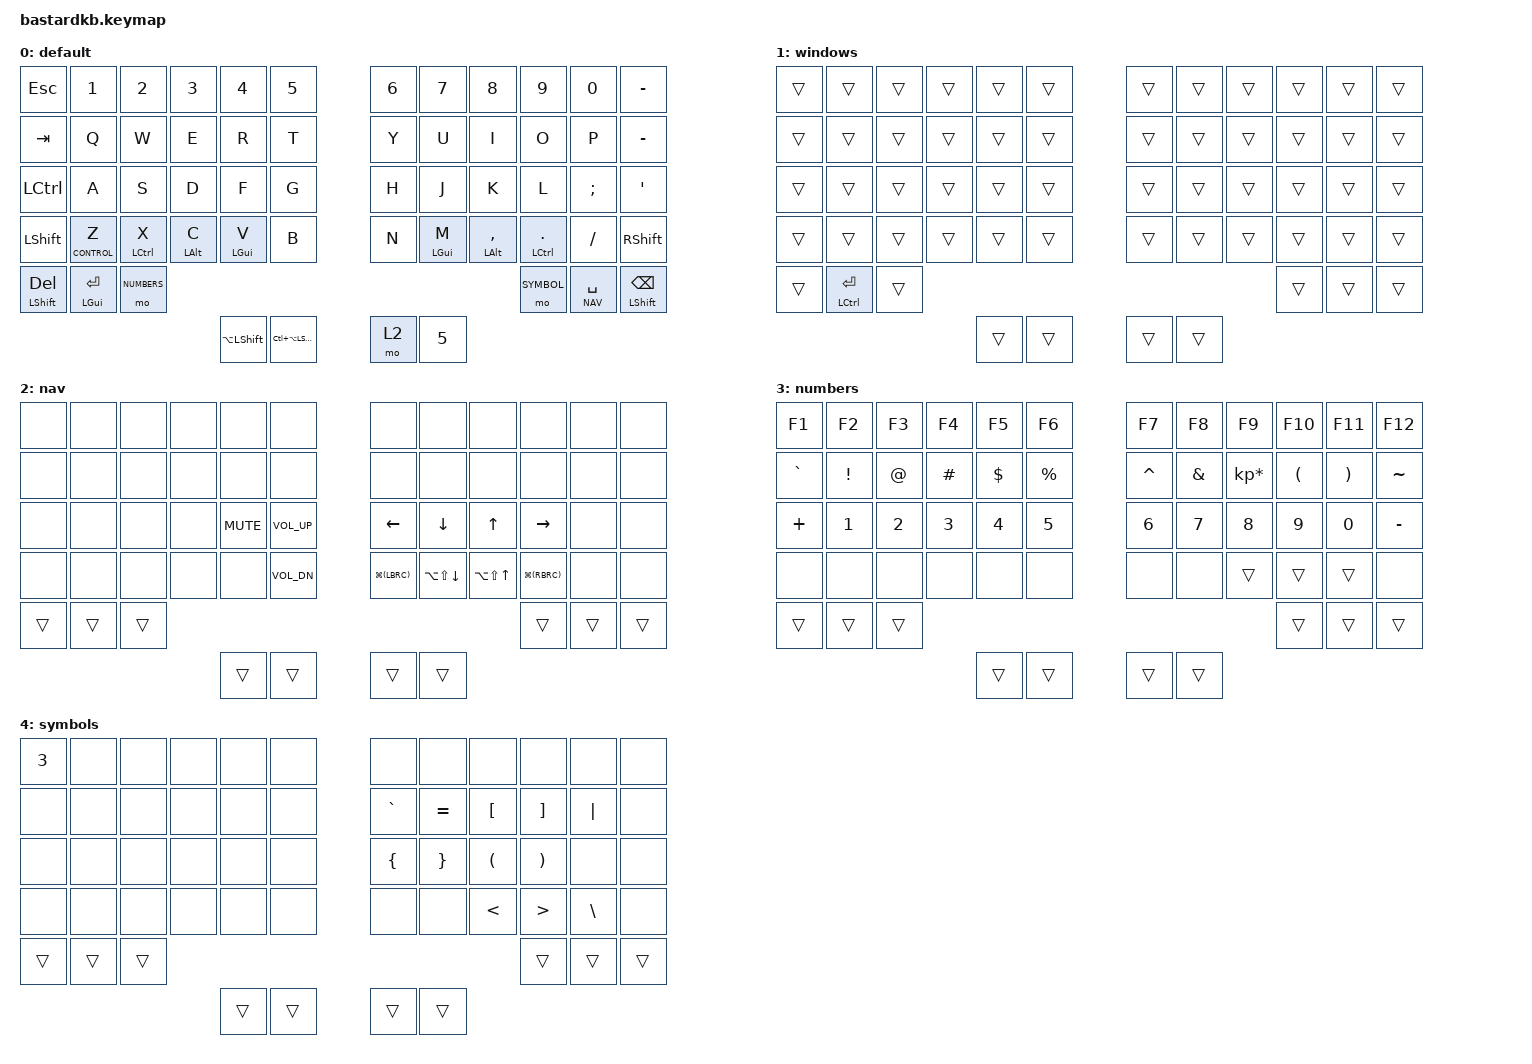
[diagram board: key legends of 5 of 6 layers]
/*
 * Copyright (c) 2020 The ZMK Contributors
 *
 * SPDX-License-Identifier: MIT
 */

#include <behaviors.dtsi>
#include <dt-bindings/zmk/keys.h>
#include <dt-bindings/zmk/bt.h>
#include <dt-bindings/zmk/ext_power.h>

#define DEFAULT 0
#define WINDOWS 1
#define NAV   2
#define NUMBERS   3
#define SYMBOL   4
#define CONTROL   5

/ {
    combos {
        compatible = "zmk,combos";
        combo_esc {
            timeout-ms = <50>;
            key-positions = <14 15>;
            bindings = <&gresc>;
        };
				combo_tab {
            timeout-ms = <50>;
            key-positions = <26 27>;
            bindings = <&kp TAB>;
        };
				combo_quote {
            timeout-ms = <50>;
            key-positions = <33 34>;
            bindings = <&kp SQT>;
        };
				combo_cmdenter {
            timeout-ms = <80>;
            key-positions = <49 54>;
            bindings = <&kp LG(RET)>;
        };
    };
};


/ {
	behaviors {
			hm: homerow_mods {
					compatible = "zmk,behavior-hold-tap";
					label = "HOMEROW_MODS";
					#binding-cells = <2>;
					tapping-term-ms = <150>;
					quick_tap_ms = <350>;
					flavor = "tap-preferred";
					bindings = <&kp>, <&kp>;
			};
	};
};
		
/ {

	keymap {
		compatible = "zmk,keymap";
		
		default {
			bindings = <
&kp ESC      &kp N1    &kp N2 &kp N3   &kp N4   &kp N5               &kp N6   &kp N7   &kp N8    &kp N9  &kp N0   &kp MINUS
&kp TAB      &kp Q     &kp W  &kp E    &kp R   &kp T               &kp Y  &kp U    &kp I     &kp O   &kp P    &kp MINUS
&kp LCTRL    &kp A     &kp S  &kp D    &kp F   &kp G               &kp H  &kp J    &kp K     &kp L   &kp SEMI &kp SQT
&kp LSHFT    &lt CONTROL Z  &hm LCTRL X &hm LALT C &hm LGUI V    &kp B               &kp N   &hm LGUI M  &hm LALT COMMA &hm LCTRL DOT &kp FSLH &kp RSHFT
&hm LSHFT DEL &hm LGUI RET  &mo NUMBERS               &mo SYMBOL &lt NAV SPACE &hm LSHFT BSPC
&kp LA(LSHFT)   &kp LC(LA(LSHFT))                                    &mo 2   &kp N5
			>;
		};
		
		windows {			
			bindings = <
&trans &trans &trans &trans &trans &trans               &trans &trans &trans &trans &trans &trans
&trans &trans &trans &trans &trans &trans               &trans &trans &trans &trans &trans &trans
&trans &trans &trans &trans &trans &trans               &trans &trans &trans &trans &trans &trans
&trans &trans &trans &trans &trans &trans               &trans &trans &trans &trans &trans &trans
&trans &hm LCTRL RET &trans               &trans &trans &trans 
&trans &trans               &trans &trans 
			>;
		};
		
	
		nav {			
			bindings = <
&none &none &none &none &none &none               &none &none &none &none &none &none
&none &none &none &none &none &none               &none &none &none &none &none &none
&none &none &none &none &kp K_MUTE &kp C_VOL_UP               &kp LEFT &kp DOWN &kp UP &kp RIGHT &none &none
&none &none &none &none &none &kp C_VOL_DN               &kp LG((LBRC)) &kp LA(LS(DOWN)) &kp LA(LS(UP)) &kp LG((RBRC)) &none &none
&trans &trans &trans               &trans &trans &trans 
&trans &trans               &trans &trans 
			>;
		};
		
		numbers {
			bindings = <
&kp F1    &kp F2 &kp F3   &kp F4   &kp F5   &kp F6               &kp F7   &kp F8   &kp F9    &kp F10  &kp F11   &kp F12
&kp GRAVE  &kp EXCL   &kp AT   &kp HASH   &kp DOLLAR   &kp PRCNT               &kp CARET  &kp AMPS   &kp KP_MULTIPLY   &kp LPAR   &kp RPAR   &kp TILDE
&kp PLUS      &kp N1    &kp N2 &kp N3   &kp N4   &kp N5               &kp N6   &kp N7   &kp N8    &kp N9  &kp N0   &kp MINUS
&none &none &none &none &none &none               &none &none &trans &trans &trans &none
&trans &trans &trans               &trans &trans &trans 
&trans &trans               &trans &trans 
			>;
		};
		
		symbols {
			bindings = <
&kp N3 &none &none &none &none &none              &none &none &none &none &none &none
&none &none &none &none &none &none               &kp GRAVE &kp EQUAL &kp LBKT &kp RBKT &kp PIPE &none
&none &none &none &none &none &none               &kp LBRC &kp RBRC &kp LPAR &kp RPAR &none &none
&none &none &none &none &none &none               &none &none &kp LT &kp GT &kp BSLH  &none
&trans &trans &trans               &trans &trans &trans 
&trans &trans               &trans &trans 
			>;
		};
		
		control {
			bindings = <
&bootloader  &bt BT_SEL 0 &bt BT_SEL 1 &none &none &none              &kp N6 &bt BT_SEL 1 &bt BT_SEL 0 &bt BT_CLR &reset &bootloader
&reset  &tog WINDOWS  &none &none &none               &none &none &none &none &none &none
&none &none &none &none &none &none               &none &none &none &none &none &none
&none &none &none &none &none &bt BT_CLR              &none &none &none &none &none &none
&trans &trans &trans               &trans &trans &trans 
&trans &trans               &trans &trans 
			>;
		};
	
	};
};

